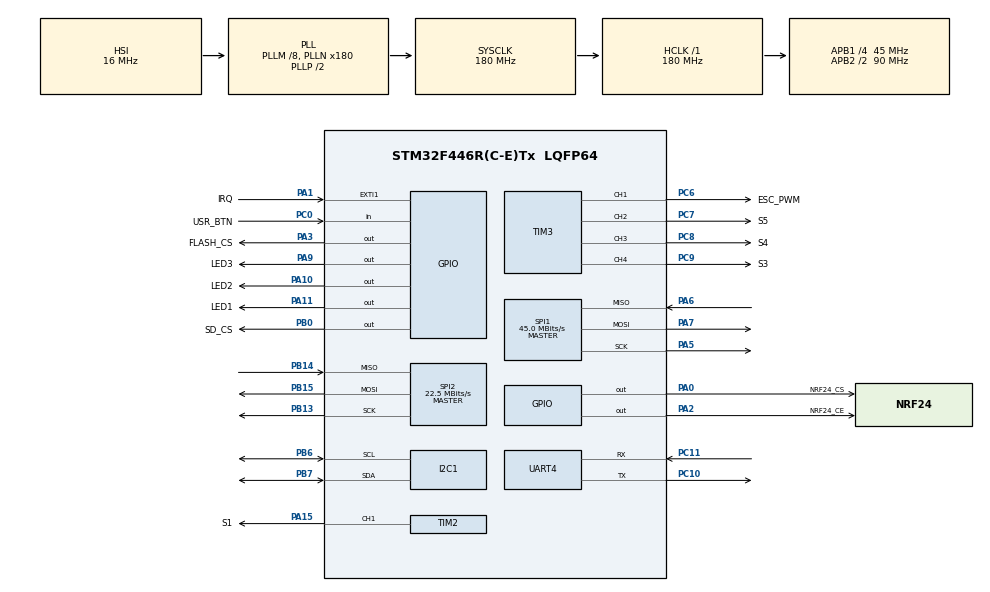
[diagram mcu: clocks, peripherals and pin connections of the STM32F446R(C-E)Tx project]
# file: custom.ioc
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Dma.I2C1_RX.4.Direction=DMA_PERIPH_TO_MEMORY
Dma.I2C1_RX.4.FIFOMode=DMA_FIFOMODE_DISABLE
Dma.I2C1_RX.4.Instance=DMA1_Stream0
Dma.I2C1_RX.4.MemDataAlignment=DMA_MDATAALIGN_BYTE
Dma.I2C1_RX.4.MemInc=DMA_MINC_ENABLE
Dma.I2C1_RX.4.Mode=DMA_NORMAL
Dma.I2C1_RX.4.PeriphDataAlignment=DMA_PDATAALIGN_BYTE
Dma.I2C1_RX.4.PeriphInc=DMA_PINC_DISABLE
Dma.I2C1_RX.4.Priority=DMA_PRIORITY_LOW
Dma.I2C1_TX.5.Direction=DMA_MEMORY_TO_PERIPH
Dma.I2C1_TX.5.FIFOMode=DMA_FIFOMODE_DISABLE
Dma.I2C1_TX.5.Instance=DMA1_Stream6
Dma.I2C1_TX.5.MemDataAlignment=DMA_MDATAALIGN_BYTE
Dma.I2C1_TX.5.MemInc=DMA_MINC_ENABLE
Dma.I2C1_TX.5.Mode=DMA_NORMAL
Dma.I2C1_TX.5.PeriphDataAlignment=DMA_PDATAALIGN_BYTE
Dma.I2C1_TX.5.PeriphInc=DMA_PINC_DISABLE
Dma.I2C1_TX.5.Priority=DMA_PRIORITY_LOW
Dma.Request0=SPI1_TX
Dma.Request1=SPI1_RX
Dma.Request2=SPI2_RX
Dma.Request3=SPI2_TX
Dma.Request4=I2C1_RX
Dma.Request5=I2C1_TX
Dma.SPI1_RX.1.Direction=DMA_PERIPH_TO_MEMORY
Dma.SPI1_RX.1.FIFOMode=DMA_FIFOMODE_DISABLE
Dma.SPI1_RX.1.Instance=DMA2_Stream0
Dma.SPI1_RX.1.MemDataAlignment=DMA_MDATAALIGN_BYTE
Dma.SPI1_RX.1.MemInc=DMA_MINC_ENABLE
Dma.SPI1_RX.1.Mode=DMA_NORMAL
Dma.SPI1_RX.1.PeriphDataAlignment=DMA_PDATAALIGN_BYTE
Dma.SPI1_RX.1.PeriphInc=DMA_PINC_DISABLE
Dma.SPI1_RX.1.Priority=DMA_PRIORITY_LOW
Dma.SPI1_TX.0.Direction=DMA_MEMORY_TO_PERIPH
Dma.SPI1_TX.0.FIFOMode=DMA_FIFOMODE_DISABLE
Dma.SPI1_TX.0.Instance=DMA2_Stream3
Dma.SPI1_TX.0.MemDataAlignment=DMA_MDATAALIGN_BYTE
Dma.SPI1_TX.0.MemInc=DMA_MINC_ENABLE
Dma.SPI1_TX.0.Mode=DMA_NORMAL
Dma.SPI1_TX.0.PeriphDataAlignment=DMA_PDATAALIGN_BYTE
Dma.SPI1_TX.0.PeriphInc=DMA_PINC_DISABLE
Dma.SPI1_TX.0.Priority=DMA_PRIORITY_LOW
Dma.SPI2_RX.2.Direction=DMA_PERIPH_TO_MEMORY
Dma.SPI2_RX.2.FIFOMode=DMA_FIFOMODE_DISABLE
Dma.SPI2_RX.2.Instance=DMA1_Stream3
Dma.SPI2_RX.2.MemDataAlignment=DMA_MDATAALIGN_BYTE
Dma.SPI2_RX.2.MemInc=DMA_MINC_ENABLE
Dma.SPI2_RX.2.Mode=DMA_NORMAL
Dma.SPI2_RX.2.PeriphDataAlignment=DMA_PDATAALIGN_BYTE
Dma.SPI2_RX.2.PeriphInc=DMA_PINC_DISABLE
Dma.SPI2_RX.2.Priority=DMA_PRIORITY_LOW
Dma.SPI2_TX.3.Direction=DMA_MEMORY_TO_PERIPH
Dma.SPI2_TX.3.FIFOMode=DMA_FIFOMODE_DISABLE
Dma.SPI2_TX.3.Instance=DMA1_Stream4
Dma.SPI2_TX.3.MemDataAlignment=DMA_MDATAALIGN_BYTE
Dma.SPI2_TX.3.MemInc=DMA_MINC_ENABLE
Dma.SPI2_TX.3.Mode=DMA_NORMAL
Dma.SPI2_TX.3.PeriphDataAlignment=DMA_PDATAALIGN_BYTE
Dma.SPI2_TX.3.PeriphInc=DMA_PINC_DISABLE
Dma.SPI2_TX.3.Priority=DMA_PRIORITY_LOW
FREERTOS.Tasks01=defaultTask,24,128,StartDefaultTask,Default,NULL,Dynamic,NULL,NULL
Mcu.Family=STM32F4
Mcu.Name=STM32F446R(C-E)Tx
Mcu.Package=LQFP64
NVIC.DMA1_Stream0_IRQn=true\:5\:0\:false\:false\:true\:true\:false\:true\:true
NVIC.DMA1_Stream3_IRQn=true\:5\:0\:false\:false\:true\:true\:false\:true\:true
NVIC.DMA1_Stream4_IRQn=true\:5\:0\:false\:false\:true\:true\:false\:true\:true
NVIC.DMA1_Stream6_IRQn=true\:5\:0\:false\:false\:true\:true\:false\:true\:true
NVIC.DMA2_Stream0_IRQn=true\:5\:0\:false\:false\:true\:true\:false\:true\:true
NVIC.DMA2_Stream3_IRQn=true\:5\:0\:false\:false\:true\:true\:false\:true\:true
NVIC.PriorityGroup=NVIC_PRIORITYGROUP_4
NVIC.TIM1_UP_TIM10_IRQn=true\:15\:0\:false\:false\:true\:false\:false\:true\:true
NVIC.TimeBase=TIM1_UP_TIM10_IRQn
NVIC.TimeBaseIP=TIM1
PA0-WKUP.GPIO_Label=NRF24_CS
PA0-WKUP.Signal=GPIO_Output
PA1.GPIO_Label=IRQ
PA1.Signal=GPXTI1
PA10.GPIO_Label=LED2
PA10.Signal=GPIO_Output
PA11.GPIO_Label=LED1
PA11.Signal=GPIO_Output
PA13.Mode=Trace_Asynchronous_SW
PA13.Signal=SYS_JTMS-SWDIO
PA14.Mode=Trace_Asynchronous_SW
PA14.Signal=SYS_JTCK-SWCLK
PA15.GPIO_Label=S1
PA15.Signal=S_TIM2_CH1_ETR
PA2.GPIO_Label=NRF24_CE
PA2.Signal=GPIO_Output
PA3.GPIO_Label=FLASH_CS
PA3.Signal=GPIO_Output
PA5.Mode=Full_Duplex_Master
PA5.Signal=SPI1_SCK
PA6.Mode=Full_Duplex_Master
PA6.Signal=SPI1_MISO
PA7.Mode=Full_Duplex_Master
PA7.Signal=SPI1_MOSI
PA9.GPIO_Label=LED3
PA9.Signal=GPIO_Output
PB0.GPIO_Label=SD_CS
PB0.Signal=GPIO_Output
PB13.Mode=Full_Duplex_Master
PB13.Signal=SPI2_SCK
PB14.Mode=Full_Duplex_Master
PB14.Signal=SPI2_MISO
PB15.Mode=Full_Duplex_Master
PB15.Signal=SPI2_MOSI
PB3.Mode=Trace_Asynchronous_SW
PB3.Signal=SYS_JTDO-SWO
PB6.Mode=I2C
PB6.Signal=I2C1_SCL
PB7.Mode=I2C
PB7.Signal=I2C1_SDA
PC0.GPIO_Label=USR_BTN
PC0.Signal=GPIO_Input
PC10.Mode=Asynchronous
PC10.Signal=UART4_TX
PC11.Mode=Asynchronous
PC11.Signal=UART4_RX
PC6.GPIO_Label=ESC_PWM
PC6.Signal=S_TIM3_CH1
PC7.GPIO_Label=S5
PC7.Signal=S_TIM3_CH2
PC8.GPIO_Label=S4
PC8.Signal=S_TIM3_CH3
PC9.GPIO_Label=S3
PC9.Signal=S_TIM3_CH4
PH0-OSC_IN.Mode=HSE-External-Oscillator
PH0-OSC_IN.Signal=RCC_OSC_IN
PH1-OSC_OUT.Mode=HSE-External-Oscillator
PH1-OSC_OUT.Signal=RCC_OSC_OUT
ProjectManager.HeapSize=0x200
ProjectManager.StackSize=0x400
ProjectManager.TargetToolchain=CMake
RCC.AHBFreq_Value=180000000
RCC.APB1CLKDivider=RCC_HCLK_DIV4
RCC.APB1Freq_Value=45000000
RCC.APB1TimFreq_Value=90000000
RCC.APB2CLKDivider=RCC_HCLK_DIV2
RCC.APB2Freq_Value=90000000
RCC.APB2TimFreq_Value=180000000
RCC.CortexFreq_Value=180000000
RCC.HCLKFreq_Value=180000000
RCC.HSE_VALUE=26000000
RCC.PLLM=8
RCC.PLLN=180
RCC.SYSCLKFreq_VALUE=180000000
RCC.SYSCLKSource=RCC_SYSCLKSOURCE_PLLCLK
RCC.USBFreq_Value=180000000
RCC.VCOOutputFreq_Value=360000000
SH.S_TIM2_CH1_ETR.0=TIM2_CH1,PWM Generation1 CH1
SH.S_TIM3_CH1.0=TIM3_CH1,PWM Generation1 CH1
SH.S_TIM3_CH2.0=TIM3_CH2,PWM Generation2 CH2
SH.S_TIM3_CH3.0=TIM3_CH3,PWM Generation3 CH3
SH.S_TIM3_CH4.0=TIM3_CH4,PWM Generation4 CH4
SPI1.CalculateBaudRate=45.0 MBits/s
SPI1.Direction=SPI_DIRECTION_2LINES
SPI1.Mode=SPI_MODE_MASTER
SPI1.VirtualType=VM_MASTER
SPI2.CalculateBaudRate=22.5 MBits/s
SPI2.Direction=SPI_DIRECTION_2LINES
SPI2.Mode=SPI_MODE_MASTER
SPI2.VirtualType=VM_MASTER
TIM2.Channel-PWM\ Generation1\ CH1=TIM_CHANNEL_1
TIM3.Channel-PWM\ Generation1\ CH1=TIM_CHANNEL_1
TIM3.Channel-PWM\ Generation2\ CH2=TIM_CHANNEL_2
TIM3.Channel-PWM\ Generation3\ CH3=TIM_CHANNEL_3
TIM3.Channel-PWM\ Generation4\ CH4=TIM_CHANNEL_4
UART4.VirtualMode=Asynchronous
VP_FATFS_VS_Generic.Mode=User_defined
VP_FREERTOS_VS_CMSIS_V2.Mode=CMSIS_V2
VP_SYS_VS_tim1.Mode=TIM1
board=custom

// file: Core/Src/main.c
/* USER CODE BEGIN Header */
/**
 ******************************************************************************
 * @file           : main.c
 * @brief          : Main program body
 ******************************************************************************
 * @attention
 *
 * Copyright (c) 2026 STMicroelectronics.
 * All rights reserved.
 *
 * This software is licensed under terms that can be found in the
 *LICENSE file in the root directory of this software component. If no
 *LICENSE file comes with this software, it is provided AS-IS.
 *
 ******************************************************************************
 */
/* USER CODE END Header */
/* Includes
 * ------------------------------------------------------------------*/
#include "main.h"
#include "cmsis_os.h"
#include "dma.h"
#include "fatfs.h"
#include "gpio.h"
#include "i2c.h"
#include "spi.h"
#include "tim.h"
#include "usart.h"

/* Private includes
 * ----------------------------------------------------------*/
/* USER CODE BEGIN Includes */
#include "app/app.hpp"

/* USER CODE END Includes */

/* Private typedef
 * -----------------------------------------------------------*/

/* Private define
 * ------------------------------------------------------------*/

/* Private macro
 * -------------------------------------------------------------*/

/* Private variables
 * ---------------------------------------------------------*/

/* Private function prototypes
 * -----------------------------------------------*/
void SystemClock_Config(void);
void MX_FREERTOS_Init(void);

/* Private user code
 * ---------------------------------------------------------*/

int main(void) {

    /* MCU
     * Configuration--------------------------------------------------------*/

    /* Reset of all peripherals, Initializes the Flash interface and
     * the Systick. */
    HAL_Init();

    /* Configure the system clock */
    SystemClock_Config();

    /* Initialize all configured peripherals */
    MX_GPIO_Init();
    MX_DMA_Init();
    MX_I2C1_Init();
    MX_SPI1_Init();
    MX_SPI2_Init();
    MX_TIM2_Init();
    MX_TIM3_Init();
    MX_UART4_Init();
    MX_FATFS_Init();
    /* USER CODE BEGIN 2 */
    {
        static const uint8_t k_boot[] =
            "\r\n[boot] gambos custom — UART4 @ 115200 (main, before "
            "scheduler)\r\n";
        (void)HAL_UART_Transmit(
            &huart4, k_boot, sizeof(k_boot) - 1U, HAL_MAX_DELAY);
        /* Bring-up: blink LED3 ~5x/s so you can prove firmware
         * reached here without UART. */
        // for (uint32_t i = 0U; i < 25U; i++) {
        //   HAL_GPIO_TogglePin(LED3_GPIO_Port, LED3_Pin);
        //   HAL_Delay(100U);
        // }
    }
    app_init();

    /* USER CODE END 2 */

    /* Init scheduler */
    osKernelInitialize(); /* Call init function for freertos objects
                             (in cmsis_os2.c) */
    MX_FREERTOS_Init();

    /* Start scheduler */
    osKernelStart();

    /* We should never get here as control is now taken by the
     * scheduler */

    /* Infinite loop */
    while (1) {

    }
}

void SystemClock_Config(void) {
    RCC_OscInitTypeDef RCC_OscInitStruct = {0};
    RCC_ClkInitTypeDef RCC_ClkInitStruct = {0};

    /** Configure the main internal regulator output voltage
     */
    __HAL_RCC_PWR_CLK_ENABLE();
    __HAL_PWR_VOLTAGESCALING_CONFIG(PWR_REGULATOR_VOLTAGE_SCALE1);

    /** Initializes the RCC Oscillators according to the specified
     * parameters in the RCC_OscInitTypeDef structure.
     */
    RCC_OscInitStruct.OscillatorType = RCC_OSCILLATORTYPE_HSI;
    RCC_OscInitStruct.HSIState = RCC_HSI_ON;
    RCC_OscInitStruct.HSICalibrationValue =
        RCC_HSICALIBRATION_DEFAULT;
    RCC_OscInitStruct.PLL.PLLState = RCC_PLL_ON;
    RCC_OscInitStruct.PLL.PLLSource = RCC_PLLSOURCE_HSI;
    RCC_OscInitStruct.PLL.PLLM = 8;
    RCC_OscInitStruct.PLL.PLLN = 180;
    RCC_OscInitStruct.PLL.PLLP = RCC_PLLP_DIV2;
    RCC_OscInitStruct.PLL.PLLQ = 2;
    RCC_OscInitStruct.PLL.PLLR = 2;
    if (HAL_RCC_OscConfig(&RCC_OscInitStruct) != HAL_OK) {
        Error_Handler();
    }

    /** Activate the Over-Drive mode
     */
    if (HAL_PWREx_EnableOverDrive() != HAL_OK) {
        Error_Handler();
    }

    /** Initializes the CPU, AHB and APB buses clocks
     */
    RCC_ClkInitStruct.ClockType =
        RCC_CLOCKTYPE_HCLK | RCC_CLOCKTYPE_SYSCLK |
        RCC_CLOCKTYPE_PCLK1 | RCC_CLOCKTYPE_PCLK2;
    RCC_ClkInitStruct.SYSCLKSource = RCC_SYSCLKSOURCE_PLLCLK;
    RCC_ClkInitStruct.AHBCLKDivider = RCC_SYSCLK_DIV1;
    RCC_ClkInitStruct.APB1CLKDivider = RCC_HCLK_DIV4;
    RCC_ClkInitStruct.APB2CLKDivider = RCC_HCLK_DIV2;

    if (HAL_RCC_ClockConfig(&RCC_ClkInitStruct, FLASH_LATENCY_5) !=
        HAL_OK) {
        Error_Handler();
    }
}

void HAL_TIM_PeriodElapsedCallback(TIM_HandleTypeDef *htim) {
    if (htim->Instance == TIM1) {
        HAL_IncTick();
    }
}

void Error_Handler(void) {
    /* USER CODE BEGIN Error_Handler_Debug */
    /* User can add his own implementation to report the HAL error
     * return state */
    __disable_irq();
    while (1) {}
    /* USER CODE END Error_Handler_Debug */
}
#ifdef USE_FULL_ASSERT
/**
 * @brief  Reports the name of the source file and the source line
 * number where the assert_param error has occurred.
 * @param  file: pointer to the source file name
 * @param  line: assert_param error line source number
 * @retval None
 */
void assert_failed(uint8_t *file, uint32_t line) {
    /* USER CODE BEGIN 6 */
    /* User can add his own implementation to report the file name and
       line number, ex: printf("Wrong parameters value: file %s on
       line %d\r\n", file, line) */
    /* USER CODE END 6 */
}
#endif /* USE_FULL_ASSERT */

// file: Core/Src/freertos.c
/* USER CODE BEGIN Header */
/**
 ******************************************************************************
 * File Name          : freertos.c
 * Description        : Code for freertos applications
 ******************************************************************************
 * @attention
 *
 * Copyright (c) 2026 STMicroelectronics.
 * All rights reserved.
 *
 * This software is licensed under terms that can be found in the
 *LICENSE file in the root directory of this software component. If no
 *LICENSE file comes with this software, it is provided AS-IS.
 *
 ******************************************************************************
 */
/* USER CODE END Header */

/* Includes
 * ------------------------------------------------------------------*/
#include "FreeRTOS.h"
#include "cmsis_os.h"
#include "main.h"
#include "task.h"

/* Private includes
 * ----------------------------------------------------------*/
/* USER CODE BEGIN Includes */
#include "app/app.hpp"
/* USER CODE END Includes */

/* Private typedef
 * -----------------------------------------------------------*/

/* Private define
 * ------------------------------------------------------------*/

/* Private macro
 * -------------------------------------------------------------*/

/* Private variables
 * ---------------------------------------------------------*/
/* Definitions for defaultTask */
osThreadId_t defaultTaskHandle;
const osThreadAttr_t defaultTask_attributes = {
    .name = "defaultTask",
    .stack_size = 256 * 4,
    .priority = (osPriority_t)osPriorityNormal,
};

/* Private function prototypes
 * -----------------------------------------------*/

void StartDefaultTask(void *argument);

void MX_FREERTOS_Init(void); /* (MISRA C 2004 rule 8.1) */

void MX_FREERTOS_Init(void) {

    /* Create the thread(s) */
    /* creation of defaultTask */
    defaultTaskHandle =
        osThreadNew(StartDefaultTask, NULL, &defaultTask_attributes);

}

void StartDefaultTask(void *argument) {
    /* USER CODE BEGIN StartDefaultTask */
    (void)argument;
    for (;;) {
        osDelay(portMAX_DELAY);
    }
    /* USER CODE END StartDefaultTask */
}

/* Private application code
 * --------------------------------------------------*/
